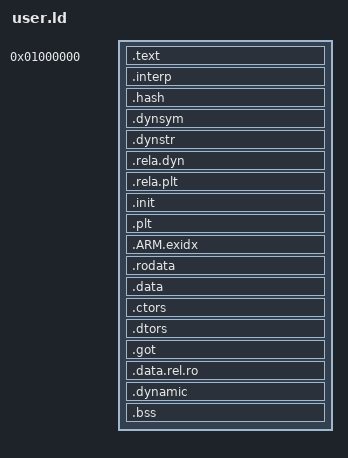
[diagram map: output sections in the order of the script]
/*
// Copyright 2016 The Fuchsia Authors
//
// Use of this source code is governed by a MIT-style
// license that can be found in the LICENSE file or at
// https://opensource.org/licenses/MIT
*/

OUTPUT_FORMAT("elf64-littleaarch64", "elf64-bigaarch64", "elf64-littleaarch64")
OUTPUT_ARCH(aarch64)

ENTRY(_start)
SECTIONS
{
    . = 0x01000000; /* base of user space */

    /* bump forward so the load offset and file offset are 1:1 */
    . += SIZEOF_HEADERS;

    /* text/read-only data */
    .text : {
        *(.crt)
        *(.text* .sram.text.glue_7* .gnu.linkonce.t.*)
    }

    .interp : { *(.interp) }
    .hash : { *(.hash) }
    .dynsym : { *(.dynsym) }
    .dynstr : { *(.dynstr) }
    .rela.dyn : {
        *(.rela.init)
        *(.rela.text .rela.text.* .rela.gnu.linkonce.t.*)
        *(.rela.fini)
        *(.rela.rodata .rela.rodata.* .rela.gnu.linkonce.r.*)
        *(.rela.data .rela.data.* .rela.gnu.linkonce.d.*)
        *(.rela.tdata .rela.tdata.* .rela.gnu.linkonce.td.*)
        *(.rela.tbss .rela.tbss.* .rela.gnu.linkonce.tb.*)
        *(.rela.ctors)
        *(.rela.dtors)
        *(.rela.got)
        *(.rela.bss .rela.bss.* .rela.gnu.linkonce.b.*)
        *(.rela.ifunc)
    }
    .rela.plt : {
        *(.rela.plt)
        PROVIDE_HIDDEN (__rela_iplt_start = .);
        *(.rela.iplt)
        PROVIDE_HIDDEN (__rela_iplt_end = .);
    }
    .init : { *(.init) } =0x9090
    .plt : { *(.plt) }

    /* .ARM.exidx is sorted, so has to go in its own output section.  */
    __exidx_start = .;
    .ARM.exidx : { *(.ARM.exidx* .gnu.linkonce.armexidx.*) }
    __exidx_end = .;

    .rodata : ALIGN(8) {
        __rodata_start = .;
        *(.rodata .rodata.* .gnu.linkonce.r.*)
        __rodata_end = .;
    }

    .data : ALIGN(4096) {
        /* writable data  */
        __data_start = .;
        *(.data .data.* .gnu.linkonce.d.*)
    }

    .ctors : ALIGN(8) {
        __ctor_list = .;
        KEEP(*(.ctors .init_array))
        __ctor_end = .;
    }
    .dtors : ALIGN(8) {
        __dtor_list = .;
        KEEP(*(.dtors .fini_array))
        __dtor_end = .;
    }
    .got : { *(.got.plt) *(.got) }
    .data.rel.ro : { *(.data.rel.ro.local* .gnu.linkonce.d.rel.ro.local.*) *(.data.rel.ro .data.rel.ro.* .gnu.linkonce.d.rel.ro.*) }
    .dynamic : { *(.dynamic) }

    __data_end = .;

    /* unintialized data (in same segment as writable data) */
    .bss : ALIGN(8) {
        __bss_start = .;
        *(.bss .bss.*)
        *(.gnu.linkonce.b.*)
        *(COMMON)
        __bss_end = .;
    }

    _end = .;

    /* Strip unnecessary stuff */
    /DISCARD/ : { *(.comment .note) }
}
